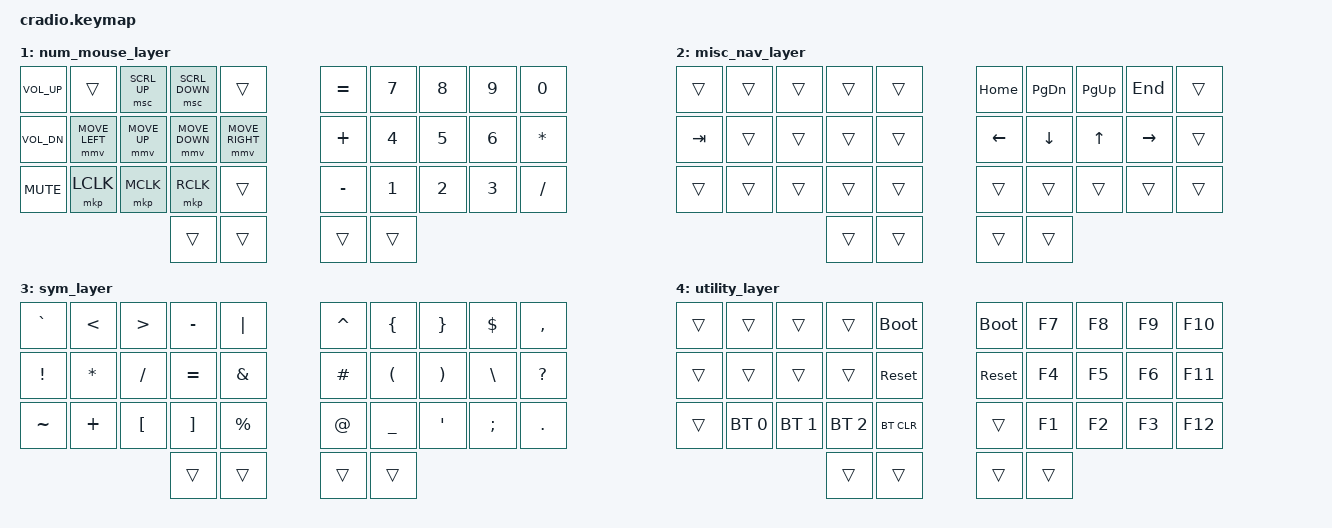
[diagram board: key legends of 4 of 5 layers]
// Copyright (c) 2022 The ZMK Contributors
// SPDX-License-Identifier: MIT

#include <behaviors.dtsi>
#include <dt-bindings/zmk/keys.h>
#include <dt-bindings/zmk/pointing.h>
#include <dt-bindings/zmk/bt.h>

// Home row mods macro
#define HRML(k1,k2,k3,k4) &hml LGUI k1  &hml LALT k2  &hml LCTRL k3  &hml LSHFT k4
#define HRMR(k1,k2,k3,k4) &hmr RSHFT k1  &hmr RCTRL k2  &hmr RALT k3  &hmr RGUI k4

/ {
    behaviors {
        hml: home_row_mod_left {
            compatible = "zmk,behavior-hold-tap";
            #binding-cells = <2>;
            flavor = "balanced";
            require-prior-idle-ms = <150>;
            tapping-term-ms = <280>;
            quick-tap-ms = <200>;
            bindings = <&kp>, <&kp>;
            hold-trigger-key-positions = < 5 6 7 8 9 15 16 17 18 19 25 26 27 28 29 >; // List of keys on the right side of the keyboard
            hold-trigger-on-release;
        };
        hmr: home_row_mod_right {
            compatible = "zmk,behavior-hold-tap";
            #binding-cells = <2>;
            flavor = "balanced";
            require-prior-idle-ms = <150>;
            tapping-term-ms = <280>;
            quick-tap-ms = <200>;
            bindings = <&kp>, <&kp>;
            hold-trigger-key-positions = < 0 1 2 3 4 10 11 12 13 14 20 21 22 23 24 >; // List of keys on the left side of the keyboard
            hold-trigger-on-release;
        };

        lt: layer_tap {
            compatible = "zmk,behavior-hold-tap";
            #binding-cells = <2>;
            flavor = "tap-preferred";
            tapping-term-ms = <200>;
	    quick-tap-ms = <200>;
            bindings = <&mo>, <&kp>;
            display-name = "Layer-Tap";
        };
    };

    conditional_layers {
        compatible = "zmk,conditional-layers";
        tri_layer {
            if-layers = <1 2>;
            then-layer = <4>;
        };
    };

    keymap {
        compatible = "zmk,keymap";
        default_layer {
            bindings = <
        //╭──────────┬──────────┬──────────┬──────────┬──────────╮   ╭──────────┬──────────┬──────────┬──────────┬──────────╮
        //│  B       │  L       │  D       │  C       │  V       │   │   J      │  F       │  O       │  U       │  , <     │
            &kp B      &kp L      &kp D      &kp C      &kp V          &kp J      &kp F      &kp O      &kp U      &kp COMMA
        //├──────────┼──────────┼──────────┼──────────┼──────────┤   ├──────────┼──────────┼──────────┼──────────┼──────────┤
        //│  N       │  R       │  T       │  S       │  G       │   │  Y       │  H       │  A       │  E       │ I        │
            HRML(N,        R,         T,         S)     &kp G          &kp Y      HRMR(H,        A,         E,        I)
        //├──────────┼──────────┼──────────┼──────────┼──────────┤   ├──────────┼──────────┼──────────┼──────────┼──────────┤
        //│  X       │  Q       │  M       │  W       │  Z       │   │  K       │  P       │ ' "      │ ; :      │ . >      │
            &kp X      &kp Q      &kp M      &kp W      &kp Z          &kp K      &kp P      &kp SQT  &kp SEMI    &kp DOT
        //╰──────────┴──────────┴──────────┼──────────┼──────────┤   ├──────────┼──────────┼──────────┴──────────┴──────────╯
                                            &lt 1 ESC   &lt 3 SPACE     &lt 3 ENTER  &lt 2 BSPC
        //                                 ╰──────────┴──────────╯   ╰──────────┴──────────╯
            >;
        };
	

        num_mouse_layer {
            bindings = <
        //╭──────────┬──────────┬──────────┬──────────┬──────────╮   ╭──────────┬──────────┬──────────┬──────────┬──────────╮
        //│   Vol+   │          │  SCRL UP │SCRL DOWN │          │   │  =       │  7       │  8       │  9       │  0       │
          &kp K_VOL_UP  &trans &msc SCRL_UP &msc SCRL_DOWN &trans      &kp EQUAL  &kp N7     &kp N8     &kp N9     &kp N0
        //├──────────┼──────────┼──────────┼──────────┼──────────┤   ├──────────┼──────────┼──────────┼──────────┼──────────┤
        //│  Vol-    │ Mouse L  │ Mouse U  │  Mouse D │  Mouse R │   │  +       │  4       │  5       │  6       │  *       │
          &kp K_VOL_DN &mmv MOVE_LEFT &mmv MOVE_UP &mmv MOVE_DOWN &mmv MOVE_RIGHT &kp PLUS &kp N4    &kp N5     &kp N6     &kp ASTRK
        //├──────────┼──────────┼──────────┼──────────┼──────────┤   ├──────────┼──────────┼──────────┼──────────┼──────────┤
        //│  Vol Mt  │Mouse Lclk│Mouse Mclk│Mouse Rclk│          │   │  -       │  1       │  2       │  3       │  /       │
            &kp K_MUTE   &mkp LCLK  &mkp MCLK  &mkp RCLK   &trans         &kp MINUS  &kp N1     &kp N2     &kp N3   &kp FSLH
        //╰──────────┴──────────┴──────────┼──────────┼──────────┤   ├──────────┼──────────┼──────────┴──────────┴──────────╯
                                             &trans     &trans         &trans     &trans
        //                                 ╰──────────┴──────────╯   ╰──────────┴──────────╯
            >;
        };


        misc_nav_layer {
            bindings = <
        //╭──────────┬──────────┬──────────┬──────────┬──────────╮   ╭──────────┬──────────┬──────────┬──────────┬──────────╮
        //│          │          │          │          │          │   │ HOME     │ PG DOWN  │   PG UP  │   END    │          │
           &trans      &trans     &trans     &trans    &trans          &kp HOME  &kp PG_DN  &kp PG_UP  &kp END    &trans
        //├──────────┼──────────┼──────────┼──────────┼──────────┤   ├──────────┼──────────┼──────────┼──────────┼──────────┤
        //│ Tab      │          │          │          |          │   │  Left    │  Down    │  Up      │  Right   │          │
            &kp TAB      &trans     &trans     &trans    &trans        &kp LEFT   &kp DOWN   &kp UP     &kp RIGHT   &trans
        //├──────────┼──────────┼──────────┼──────────┼──────────┤   ├──────────┼──────────┼──────────┼──────────┼──────────┤
        //│          │          │          │          │          │   │          │          │          │          │          │
            &trans     &trans     &trans     &trans     &trans         &trans     &trans     &trans     &trans     &trans
        //╰──────────┴──────────┴──────────┼──────────┼──────────┤   ├──────────┼──────────┼──────────┴──────────┴──────────╯
                                             &trans     &trans         &trans     &trans
        //                                 ╰──────────┴──────────╯   ╰──────────┴──────────╯
            >;
        };


        sym_layer {
            bindings = <
        //╭──────────┬──────────┬──────────┬──────────┬──────────╮   ╭──────────┬──────────┬──────────┬──────────┬──────────╮
        //│ `        │  <       │  >       │  -       │ |        │   │  ^       │  {       │  }       │  $       │  ,       │
           &kp GRAVE   &kp LT     &kp GT     &kp MINUS &kp PIPE        &kp CARET  &kp LBRC   &kp RBRC   &kp DOLLAR &kp COMMA
        //├──────────┼──────────┼──────────┼──────────┼──────────┤   ├──────────┼──────────┼──────────┼──────────┼──────────┤
        //│ !        │  *       │  /       │  =       │ &        │   │  #       │  (       │  )       │  \       │ ?        │
          &kp EXCL     &kp ASTRK  &kp FSLH   &kp EQUAL &kp AMPS        &kp HASH   &kp LPAR   &kp RPAR   &kp BSLH  &kp QMARK
        //├──────────┼──────────┼──────────┼──────────┼──────────┤   ├──────────┼──────────┼──────────┼──────────┼──────────┤
        //│  ~       │  +       │  [       │ ]        │ %        │   │  @       │  _       │  '       │  ;       │  .       │
            &kp TILDE  &kp PLUS   &kp LBKT  &kp RBKT   &kp PRCNT       &kp AT     &kp UNDER  &kp APOS   &kp SEMI   &kp DOT
        //╰──────────┴──────────┴──────────┼──────────┼──────────┤   ├──────────┼──────────┼──────────┴──────────┴──────────╯
                                             &trans     &trans         &trans     &trans
        //                                 ╰──────────┴──────────╯   ╰──────────┴──────────╯
            >;
        };


        utility_layer {
            bindings = <
        //╭──────────┬──────────┬──────────┬──────────┬──────────╮   ╭──────────┬──────────┬──────────┬──────────┬──────────╮
        //│          │          │          │          │BOOTLOADER│   │BOOTLOADER│  F7      │  F8      │  F9      │ F10      │
           &trans      &trans     &trans     &trans   &bootloader    &bootloader  &kp F7     &kp F8     &kp F9     &kp F10
        //├──────────┼──────────┼──────────┼──────────┼──────────┤   ├──────────┼──────────┼──────────┼──────────┼──────────┤
        //│          │          │          │          │  RESET   │   │  RESET   │  F4      │  F5      │  F6      │ F11      │
          &trans       &trans     &trans     &trans    &sys_reset     &sys_reset   &kp F4     &kp F5     &kp F6    &kp F11
        //├──────────┼──────────┼──────────┼──────────┼──────────┤   ├──────────┼──────────┼──────────┼──────────┼──────────┤
        //│          │ PROFILE 0│PROFILE 1 │ PROFILE 2│ BT CLEAR │   │          │  F1      │  F2      │  F3      │  F12     │
            &trans &bt BT_SEL 0 &bt BT_SEL 1 &bt BT_SEL 2 &bt BT_CLR   &trans     &kp F1     &kp F2     &kp F3     &kp F12
        //╰──────────┴──────────┴──────────┼──────────┼──────────┤   ├──────────┼──────────┼──────────┴──────────┴──────────╯
                                             &trans     &trans         &trans     &trans
        //                                 ╰──────────┴──────────╯   ╰──────────┴──────────╯
            >;
        };

    };
};
